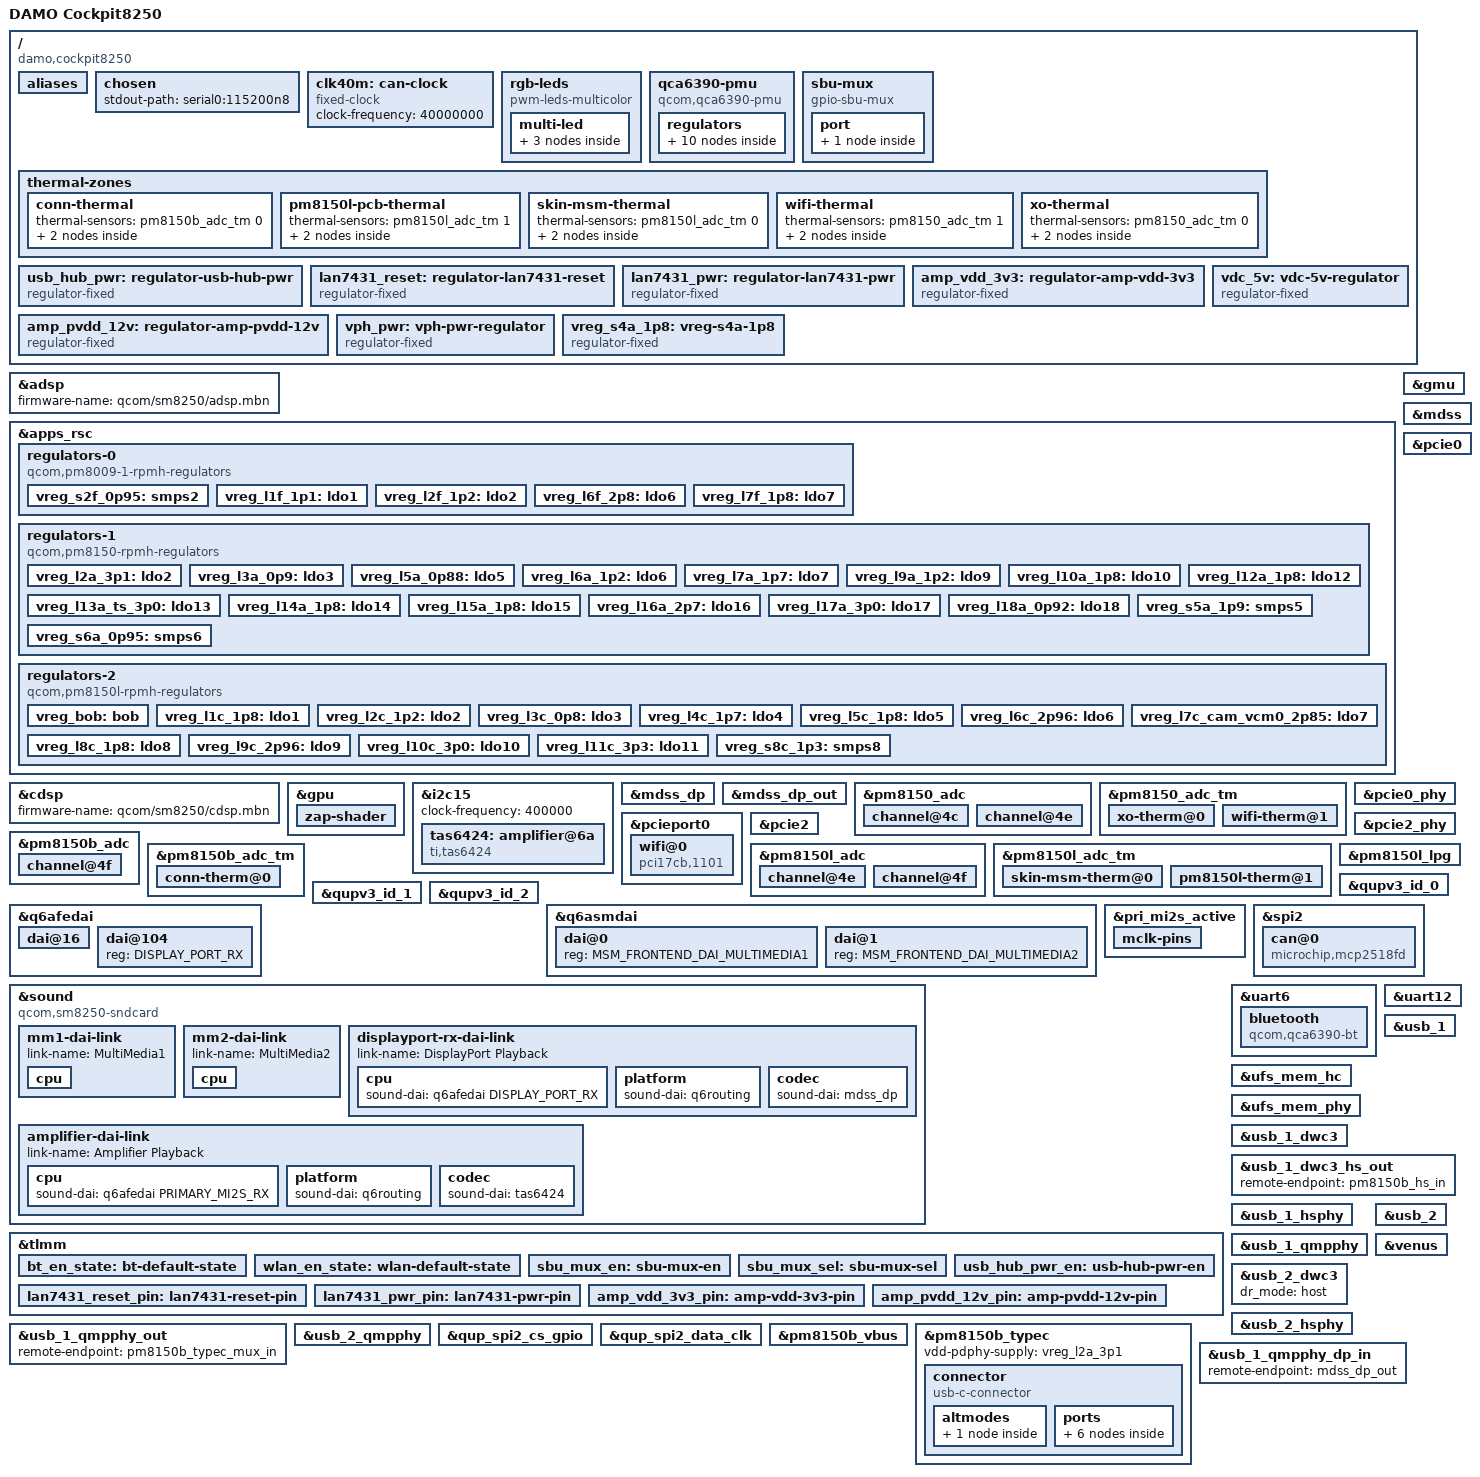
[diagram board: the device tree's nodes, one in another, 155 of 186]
// SPDX-License-Identifier: BSD-3-Clause
/*
 * Copyright (c) 2020, Linaro Ltd.
 * Copyright (c) 2025 retro98boy <retro98boy@qq.com>
 */

/dts-v1/;

#include <dt-bindings/leds/common.h>
#include <dt-bindings/regulator/qcom,rpmh-regulator.h>
#include <dt-bindings/sound/qcom,q6afe.h>
#include <dt-bindings/sound/qcom,q6asm.h>
#include <dt-bindings/usb/pd.h>
#include "sm8250.dtsi"
#include "pm8150.dtsi"
#include "pm8150b.dtsi"
#include "pm8150l.dtsi"

/ {
	model = "DAMO Cockpit8250";
	compatible = "damo,cockpit8250", "qcom,sm8250";
	/* required for abl to select correct board */
	qcom,msm-id = <0x1e1 0x20001>;
	qcom,board-id = <0x1001f 0x01>;

	aliases {
		serial0 = &uart12;
		serial1 = &uart6;
	};

	chosen {
		stdout-path = "serial0:115200n8";
	};

	clk40m: can-clock {
		compatible = "fixed-clock";
		#clock-cells = <0>;
		clock-frequency = <40000000>;
	};

	rgb-leds {
		compatible = "pwm-leds-multicolor";

		multi-led {
			color = <LED_COLOR_ID_RGB>;
			max-brightness = <255>;

			led-red {
				color = <LED_COLOR_ID_RED>;
				pwms = <&pm8150l_lpg 0 1000000 0>;
			};

			led-green {
				color = <LED_COLOR_ID_GREEN>;
				pwms = <&pm8150l_lpg 1 1000000 0>;
			};

			led-blue {
				color = <LED_COLOR_ID_BLUE>;
				pwms = <&pm8150l_lpg 2 1000000 0>;
			};
		};
	};

	qca6390-pmu {
		compatible = "qcom,qca6390-pmu";

		pinctrl-names = "default";
		pinctrl-0 = <&bt_en_state>, <&wlan_en_state>;

		vddaon-supply = <&vreg_s6a_0p95>;
		vddpmu-supply = <&vreg_s2f_0p95>;
		vddrfa0p95-supply = <&vreg_s2f_0p95>;
		vddrfa1p3-supply = <&vreg_s8c_1p3>;
		vddrfa1p9-supply = <&vreg_s5a_1p9>;
		vddpcie1p3-supply = <&vreg_s8c_1p3>;
		vddpcie1p9-supply = <&vreg_s5a_1p9>;
		vddio-supply = <&vreg_s4a_1p8>;

		wlan-enable-gpios = <&tlmm 20 GPIO_ACTIVE_HIGH>;
		bt-enable-gpios = <&tlmm 21 GPIO_ACTIVE_HIGH>;

		regulators {
			vreg_pmu_rfa_cmn: ldo0 {
				regulator-name = "vreg_pmu_rfa_cmn";
			};

			vreg_pmu_aon_0p59: ldo1 {
				regulator-name = "vreg_pmu_aon_0p59";
			};

			vreg_pmu_wlcx_0p8: ldo2 {
				regulator-name = "vreg_pmu_wlcx_0p8";
			};

			vreg_pmu_wlmx_0p85: ldo3 {
				regulator-name = "vreg_pmu_wlmx_0p85";
			};

			vreg_pmu_btcmx_0p85: ldo4 {
				regulator-name = "vreg_pmu_btcmx_0p85";
			};

			vreg_pmu_rfa_0p8: ldo5 {
				regulator-name = "vreg_pmu_rfa_0p8";
			};

			vreg_pmu_rfa_1p2: ldo6 {
				regulator-name = "vreg_pmu_rfa_1p2";
			};

			vreg_pmu_rfa_1p7: ldo7 {
				regulator-name = "vreg_pmu_rfa_1p7";
			};

			vreg_pmu_pcie_0p9: ldo8 {
				regulator-name = "vreg_pmu_pcie_0p9";
			};

			vreg_pmu_pcie_1p8: ldo9 {
				regulator-name = "vreg_pmu_pcie_1p8";
			};
		};
	};

	sbu-mux {
		compatible = "gpio-sbu-mux";
		pinctrl-names = "default";
		pinctrl-0 = <&sbu_mux_en &sbu_mux_sel>;
		enable-gpios = <&tlmm 9 GPIO_ACTIVE_LOW>;
		select-gpios = <&tlmm 8 GPIO_ACTIVE_HIGH>;

		mode-switch;
		orientation-switch;

		port {
			sbu_mux_in: endpoint {
				remote-endpoint = <&pm8150b_typec_sbu_out>;
			};
		};
	};

	thermal-zones {
		conn-thermal {
			thermal-sensors = <&pm8150b_adc_tm 0>;

			trips {
				active-config0 {
					temperature = <125000>;
					hysteresis = <1000>;
					type = "critical";
				};
			};
		};

		pm8150l-pcb-thermal {
			thermal-sensors = <&pm8150l_adc_tm 1>;

			trips {
				active-config0 {
					temperature = <50000>;
					hysteresis = <4000>;
					type = "passive";
				};
			};
		};

		skin-msm-thermal {
			thermal-sensors = <&pm8150l_adc_tm 0>;

			trips {
				active-config0 {
					temperature = <50000>;
					hysteresis = <4000>;
					type = "passive";
				};
			};
		};

		wifi-thermal {
			thermal-sensors = <&pm8150_adc_tm 1>;

			trips {
				active-config0 {
					temperature = <52000>;
					hysteresis = <4000>;
					type = "passive";
				};
			};
		};

		xo-thermal {
			thermal-sensors = <&pm8150_adc_tm 0>;

			trips {
				active-config0 {
					temperature = <50000>;
					hysteresis = <4000>;
					type = "passive";
				};
			};
		};
	};

	usb_hub_pwr: regulator-usb-hub-pwr {
		compatible = "regulator-fixed";
		enable-active-high;
		gpio = <&tlmm 2 GPIO_ACTIVE_HIGH>;
		pinctrl-names = "default";
		pinctrl-0 = <&usb_hub_pwr_en>;
		regulator-name = "usb_hub_pwr";
		regulator-always-on;
		regulator-boot-on;
	};

	lan7431_reset: regulator-lan7431-reset {
		compatible = "regulator-fixed";
		enable-active-high;
		gpio = <&tlmm 10 GPIO_ACTIVE_HIGH>;
		pinctrl-names = "default";
		pinctrl-0 = <&lan7431_reset_pin>;
		regulator-name = "lan7431_reset";
		regulator-always-on;
		regulator-boot-on;
	};

	lan7431_pwr: regulator-lan7431-pwr {
		compatible = "regulator-fixed";
		enable-active-high;
		gpio = <&tlmm 53 GPIO_ACTIVE_HIGH>;
		pinctrl-names = "default";
		pinctrl-0 = <&lan7431_pwr_pin>;
		regulator-name = "lan7431_pwr";
		regulator-always-on;
		regulator-boot-on;
	};

	amp_vdd_3v3: regulator-amp-vdd-3v3 {
		compatible = "regulator-fixed";
		enable-active-high;
		gpio = <&tlmm 12 GPIO_ACTIVE_HIGH>;
		pinctrl-names = "default";
		pinctrl-0 = <&amp_vdd_3v3_pin>;
		regulator-name = "amp_vdd_3v3";
		regulator-always-on;
		regulator-boot-on;
	};

	amp_pvdd_12v: regulator-amp-pvdd-12v {
		compatible = "regulator-fixed";
		enable-active-high;
		gpio = <&tlmm 13 GPIO_ACTIVE_HIGH>;
		pinctrl-names = "default";
		pinctrl-0 = <&amp_pvdd_12v_pin>;
		regulator-name = "amp_pvdd_12v";
		regulator-always-on;
		regulator-boot-on;
	};

	vdc_5v: vdc-5v-regulator {
		compatible = "regulator-fixed";
		regulator-name = "VDC_5V";

		regulator-min-microvolt = <5000000>;
		regulator-max-microvolt = <5000000>;
		regulator-always-on;
		vin-supply = <&vreg_l11c_3p3>;
	};

	vph_pwr: vph-pwr-regulator {
		compatible = "regulator-fixed";
		regulator-name = "vph_pwr";
		regulator-min-microvolt = <3700000>;
		regulator-max-microvolt = <3700000>;
		regulator-always-on;
	};

	vreg_s4a_1p8: vreg-s4a-1p8 {
		compatible = "regulator-fixed";
		regulator-name = "vreg_s4a_1p8";
		regulator-min-microvolt = <1800000>;
		regulator-max-microvolt = <1800000>;
		regulator-always-on;
	};
};

&adsp {
	status = "okay";
	firmware-name = "qcom/sm8250/adsp.mbn";
};

&apps_rsc {
	regulators-0 {
		compatible = "qcom,pm8009-1-rpmh-regulators";
		qcom,pmic-id = "f";

		vdd-s1-supply = <&vph_pwr>;
		vdd-s2-supply = <&vph_pwr>;
		vdd-l2-supply = <&vreg_s8c_1p3>;
		vdd-l5-l6-supply = <&vreg_bob>;
		vdd-l7-supply = <&vreg_s4a_1p8>;

		vreg_s2f_0p95: smps2 {
			regulator-name = "vreg_s2f_0p95";
			regulator-min-microvolt = <900000>;
			regulator-max-microvolt = <952000>;
			regulator-initial-mode = <RPMH_REGULATOR_MODE_AUTO>;
		};

		vreg_l1f_1p1: ldo1 {
			regulator-name = "vreg_l1f_1p1";
			regulator-min-microvolt = <1104000>;
			regulator-max-microvolt = <1104000>;
			regulator-initial-mode = <RPMH_REGULATOR_MODE_HPM>;
		};

		vreg_l2f_1p2: ldo2 {
			regulator-name = "vreg_l2f_1p2";
			regulator-min-microvolt = <1200000>;
			regulator-max-microvolt = <1200000>;
			regulator-initial-mode = <RPMH_REGULATOR_MODE_HPM>;
		};

		vreg_l6f_2p8: ldo6 {
			regulator-name = "vreg_l6f_2p8";
			regulator-min-microvolt = <2800000>;
			regulator-max-microvolt = <2800000>;
			regulator-initial-mode = <RPMH_REGULATOR_MODE_HPM>;
		};

		vreg_l7f_1p8: ldo7 {
			regulator-name = "vreg_l7f_1p8";
			regulator-min-microvolt = <1800000>;
			regulator-max-microvolt = <1800000>;
			regulator-initial-mode = <RPMH_REGULATOR_MODE_HPM>;
		};
	};

	regulators-1 {
		compatible = "qcom,pm8150-rpmh-regulators";
		qcom,pmic-id = "a";

		vdd-s1-supply = <&vph_pwr>;
		vdd-s2-supply = <&vph_pwr>;
		vdd-s3-supply = <&vph_pwr>;
		vdd-s4-supply = <&vph_pwr>;
		vdd-s5-supply = <&vph_pwr>;
		vdd-s6-supply = <&vph_pwr>;
		vdd-s7-supply = <&vph_pwr>;
		vdd-s8-supply = <&vph_pwr>;
		vdd-s9-supply = <&vph_pwr>;
		vdd-s10-supply = <&vph_pwr>;
		vdd-l2-l10-supply = <&vreg_bob>;
		vdd-l3-l4-l5-l18-supply = <&vreg_s6a_0p95>;
		vdd-l6-l9-supply = <&vreg_s8c_1p3>;
		vdd-l7-l12-l14-l15-supply = <&vreg_s5a_1p9>;
		vdd-l13-l16-l17-supply = <&vreg_bob>;

		vreg_l2a_3p1: ldo2 {
			regulator-name = "vreg_l2a_3p1";
			regulator-min-microvolt = <3072000>;
			regulator-max-microvolt = <3072000>;
			regulator-initial-mode = <RPMH_REGULATOR_MODE_HPM>;
		};

		vreg_l3a_0p9: ldo3 {
			regulator-name = "vreg_l3a_0p9";
			regulator-min-microvolt = <928000>;
			regulator-max-microvolt = <932000>;
			regulator-initial-mode = <RPMH_REGULATOR_MODE_HPM>;
		};

		vreg_l5a_0p88: ldo5 {
			regulator-name = "vreg_l5a_0p88";
			regulator-min-microvolt = <880000>;
			regulator-max-microvolt = <880000>;
			regulator-initial-mode = <RPMH_REGULATOR_MODE_HPM>;
		};

		vreg_l6a_1p2: ldo6 {
			regulator-name = "vreg_l6a_1p2";
			regulator-min-microvolt = <1200000>;
			regulator-max-microvolt = <1200000>;
			regulator-initial-mode = <RPMH_REGULATOR_MODE_HPM>;
		};

		vreg_l7a_1p7: ldo7 {
			regulator-name = "vreg_l7a_1p7";
			regulator-min-microvolt = <1704000>;
			regulator-max-microvolt = <1800000>;
			regulator-initial-mode = <RPMH_REGULATOR_MODE_HPM>;
		};

		vreg_l9a_1p2: ldo9 {
			regulator-name = "vreg_l9a_1p2";
			regulator-min-microvolt = <1200000>;
			regulator-max-microvolt = <1200000>;
			regulator-initial-mode = <RPMH_REGULATOR_MODE_HPM>;
		};

		vreg_l10a_1p8: ldo10 {
			regulator-name = "vreg_l10a_1p8";
			regulator-min-microvolt = <1800000>;
			regulator-max-microvolt = <1800000>;
			regulator-initial-mode = <RPMH_REGULATOR_MODE_HPM>;
		};

		vreg_l12a_1p8: ldo12 {
			regulator-name = "vreg_l12a_1p8";
			regulator-min-microvolt = <1800000>;
			regulator-max-microvolt = <1800000>;
			regulator-initial-mode = <RPMH_REGULATOR_MODE_HPM>;
		};

		vreg_l13a_ts_3p0: ldo13 {
			regulator-name = "vreg_l13a_ts_3p0";
			regulator-min-microvolt = <3008000>;
			regulator-max-microvolt = <3008000>;
			regulator-initial-mode = <RPMH_REGULATOR_MODE_HPM>;
		};

		vreg_l14a_1p8: ldo14 {
			regulator-name = "vreg_l14a_1p8";
			regulator-min-microvolt = <1800000>;
			regulator-max-microvolt = <1880000>;
			regulator-initial-mode = <RPMH_REGULATOR_MODE_HPM>;
		};

		vreg_l15a_1p8: ldo15 {
			regulator-name = "vreg_l15a_1p8";
			regulator-min-microvolt = <1800000>;
			regulator-max-microvolt = <1800000>;
			regulator-initial-mode = <RPMH_REGULATOR_MODE_HPM>;
		};

		vreg_l16a_2p7: ldo16 {
			regulator-name = "vreg_l16a_2p7";
			regulator-min-microvolt = <2704000>;
			regulator-max-microvolt = <2960000>;
			regulator-initial-mode = <RPMH_REGULATOR_MODE_HPM>;
		};

		vreg_l17a_3p0: ldo17 {
			regulator-name = "vreg_l17a_3p0";
			regulator-min-microvolt = <2856000>;
			regulator-max-microvolt = <3008000>;
			regulator-initial-mode = <RPMH_REGULATOR_MODE_HPM>;
		};

		vreg_l18a_0p92: ldo18 {
			regulator-name = "vreg_l18a_0p92";
			regulator-min-microvolt = <800000>;
			regulator-max-microvolt = <912000>;
			regulator-initial-mode = <RPMH_REGULATOR_MODE_HPM>;
		};

		vreg_s5a_1p9: smps5 {
			regulator-name = "vreg_s5a_1p9";
			regulator-min-microvolt = <1904000>;
			regulator-max-microvolt = <2000000>;
			regulator-initial-mode = <RPMH_REGULATOR_MODE_HPM>;
		};

		vreg_s6a_0p95: smps6 {
			regulator-name = "vreg_s6a_0p95";
			regulator-min-microvolt = <920000>;
			regulator-max-microvolt = <1128000>;
			regulator-initial-mode = <RPMH_REGULATOR_MODE_HPM>;
		};
	};

	regulators-2 {
		compatible = "qcom,pm8150l-rpmh-regulators";
		qcom,pmic-id = "c";

		vdd-s1-supply = <&vph_pwr>;
		vdd-s2-supply = <&vph_pwr>;
		vdd-s3-supply = <&vph_pwr>;
		vdd-s4-supply = <&vph_pwr>;
		vdd-s5-supply = <&vph_pwr>;
		vdd-s6-supply = <&vph_pwr>;
		vdd-s7-supply = <&vph_pwr>;
		vdd-s8-supply = <&vph_pwr>;
		vdd-l1-l8-supply = <&vreg_s4a_1p8>;
		vdd-l2-l3-supply = <&vreg_s8c_1p3>;
		vdd-l4-l5-l6-supply = <&vreg_bob>;
		vdd-l7-l11-supply = <&vreg_bob>;
		vdd-l9-l10-supply = <&vreg_bob>;
		vdd-bob-supply = <&vph_pwr>;

		vreg_bob: bob {
			regulator-name = "vreg_bob";
			regulator-min-microvolt = <3008000>;
			regulator-max-microvolt = <4000000>;
			regulator-initial-mode = <RPMH_REGULATOR_MODE_AUTO>;
		};

		vreg_l1c_1p8: ldo1 {
			regulator-name = "vreg_l1c_1p8";
			regulator-min-microvolt = <1800000>;
			regulator-max-microvolt = <1800000>;
			regulator-initial-mode = <RPMH_REGULATOR_MODE_HPM>;
		};

		vreg_l2c_1p2: ldo2 {
			regulator-name = "vreg_l2c_1p2";
			regulator-min-microvolt = <1200000>;
			regulator-max-microvolt = <1200000>;
			regulator-initial-mode = <RPMH_REGULATOR_MODE_HPM>;
		};

		vreg_l3c_0p8: ldo3 {
			regulator-name = "vreg_l3c_0p8";
			regulator-min-microvolt = <800000>;
			regulator-max-microvolt = <800000>;
			regulator-initial-mode = <RPMH_REGULATOR_MODE_HPM>;
		};

		vreg_l4c_1p7: ldo4 {
			regulator-name = "vreg_l4c_1p7";
			regulator-min-microvolt = <1704000>;
			regulator-max-microvolt = <2928000>;
			regulator-initial-mode = <RPMH_REGULATOR_MODE_HPM>;
		};

		vreg_l5c_1p8: ldo5 {
			regulator-name = "vreg_l5c_1p8";
			regulator-min-microvolt = <1800000>;
			regulator-max-microvolt = <2928000>;
			regulator-initial-mode = <RPMH_REGULATOR_MODE_HPM>;
		};

		vreg_l6c_2p96: ldo6 {
			regulator-name = "vreg_l6c_2p96";
			regulator-min-microvolt = <1800000>;
			regulator-max-microvolt = <2960000>;
			regulator-initial-mode = <RPMH_REGULATOR_MODE_HPM>;
		};

		vreg_l7c_cam_vcm0_2p85: ldo7 {
			regulator-name = "vreg_l7c_cam_vcm0_2p85";
			regulator-min-microvolt = <2856000>;
			regulator-max-microvolt = <3104000>;
			regulator-initial-mode = <RPMH_REGULATOR_MODE_HPM>;
		};

		vreg_l8c_1p8: ldo8 {
			regulator-name = "vreg_l8c_1p8";
			regulator-min-microvolt = <1800000>;
			regulator-max-microvolt = <1800000>;
			regulator-initial-mode = <RPMH_REGULATOR_MODE_HPM>;
		};

		vreg_l9c_2p96: ldo9 {
			regulator-name = "vreg_l9c_2p96";
			regulator-min-microvolt = <2704000>;
			regulator-max-microvolt = <2960000>;
			regulator-initial-mode = <RPMH_REGULATOR_MODE_HPM>;
		};

		vreg_l10c_3p0: ldo10 {
			regulator-name = "vreg_l10c_3p0";
			regulator-min-microvolt = <3000000>;
			regulator-max-microvolt = <3000000>;
			regulator-initial-mode = <RPMH_REGULATOR_MODE_HPM>;
		};

		vreg_l11c_3p3: ldo11 {
			regulator-name = "vreg_l11c_3p3";
			regulator-min-microvolt = <3296000>;
			regulator-max-microvolt = <3296000>;
			regulator-initial-mode = <RPMH_REGULATOR_MODE_HPM>;
			regulator-always-on;
		};

		vreg_s8c_1p3: smps8 {
			regulator-name = "vreg_s8c_1p3";
			regulator-min-microvolt = <1352000>;
			regulator-max-microvolt = <1352000>;
			regulator-initial-mode = <RPMH_REGULATOR_MODE_HPM>;
		};
	};
};

&cdsp {
	status = "okay";
	firmware-name = "qcom/sm8250/cdsp.mbn";
};

&gmu {
	status = "okay";
};

&gpu {
	status = "okay";

	zap-shader {
		memory-region = <&gpu_mem>;
		firmware-name = "qcom/sm8250/a650_zap.mbn";
	};
};

&i2c15 {
	status = "okay";
	clock-frequency = <400000>;

	tas6424: amplifier@6a {
		sound-name-prefix = "Amplifier";
		compatible = "ti,tas6424";
		reg = <0x6a>;
		#sound-dai-cells = <0>;

		/* dvdd-supply = <&amp_vdd_3v3>; */
		/* pvdd-supply = <&amp_pvdd_12v>; */
		standby-gpios = <&tlmm 41 GPIO_ACTIVE_LOW>;
		mute-gpios = <&tlmm 42 GPIO_ACTIVE_LOW>;
	};
};

&mdss {
	status = "okay";
};

&mdss_dp {
	status = "okay";
};

&mdss_dp_out {
	data-lanes = <2 3>;
	remote-endpoint = <&usb_1_qmpphy_dp_in>;
};

&pm8150_adc {
	channel@4c {
		reg = <ADC5_XO_THERM_100K_PU>;
		qcom,ratiometric;
		qcom,hw-settle-time = <200>;
		label = "xo_therm";
	};

	channel@4e {
		reg = <ADC5_AMUX_THM2_100K_PU>;
		qcom,ratiometric;
		qcom,hw-settle-time = <200>;
		label = "wifi_therm";
	};
};

&pm8150_adc_tm {
	status = "okay";

	xo-therm@0 {
		reg = <0>;
		io-channels = <&pm8150_adc ADC5_XO_THERM_100K_PU>;
		qcom,ratiometric;
		qcom,hw-settle-time-us = <200>;
	};

	wifi-therm@1 {
		reg = <1>;
		io-channels = <&pm8150_adc ADC5_AMUX_THM2_100K_PU>;
		qcom,ratiometric;
		qcom,hw-settle-time-us = <200>;
	};
};

&pcie0 {
	status = "okay";
};

&pcie0_phy {
	status = "okay";
	vdda-phy-supply = <&vreg_l5a_0p88>;
	vdda-pll-supply = <&vreg_l9a_1p2>;
};

&pcieport0 {
	wifi@0 {
		compatible = "pci17cb,1101";
		reg = <0x10000 0x0 0x0 0x0 0x0>;

		vddrfacmn-supply = <&vreg_pmu_rfa_cmn>;
		vddaon-supply = <&vreg_pmu_aon_0p59>;
		vddwlcx-supply = <&vreg_pmu_wlcx_0p8>;
		vddwlmx-supply = <&vreg_pmu_wlmx_0p85>;
		vddrfa0p8-supply = <&vreg_pmu_rfa_0p8>;
		vddrfa1p2-supply = <&vreg_pmu_rfa_1p2>;
		vddrfa1p7-supply = <&vreg_pmu_rfa_1p7>;
		vddpcie0p9-supply = <&vreg_pmu_pcie_0p9>;
		vddpcie1p8-supply = <&vreg_pmu_pcie_1p8>;
	};
};

/*
 * LAN7431
 * PERST# <-> tlmm 85
 * WAKE# <-> tlmm 87
 * RESET_N <-> tlmm 10
 * AVDD12 VDD_OTP VDD12CORE VDD12_SW_FB VDD_SW_IN VDD12_SW_OUT VDD_REG_IN VDD25_REG_OUT VPH VPTX VP <-> tlmm 53
 */
&pcie2 {
	status = "okay";
};

&pcie2_phy {
	status = "okay";
	vdda-phy-supply = <&vreg_l5a_0p88>;
	vdda-pll-supply = <&vreg_l9a_1p2>;
};

&pm8150b_adc {
	channel@4f {
		reg = <ADC5_AMUX_THM3_100K_PU>;
		qcom,ratiometric;
		qcom,hw-settle-time = <200>;
		label = "conn_therm";
	};
};

&pm8150b_adc_tm {
	status = "okay";

	conn-therm@0 {
		reg = <0>;
		io-channels = <&pm8150b_adc ADC5_AMUX_THM3_100K_PU>;
		qcom,ratiometric;
		qcom,hw-settle-time-us = <200>;
	};
};

&pm8150l_adc {
	channel@4e {
		reg = <ADC5_AMUX_THM2_100K_PU>;
		qcom,ratiometric;
		qcom,hw-settle-time = <200>;
		label = "skin_msm_therm";
	};

	channel@4f {
		reg = <ADC5_AMUX_THM3_100K_PU>;
		qcom,ratiometric;
		qcom,hw-settle-time = <200>;
		label = "pm8150l_therm";
	};
};

&pm8150l_adc_tm {
	status = "okay";

	skin-msm-therm@0 {
		reg = <0>;
		io-channels = <&pm8150l_adc ADC5_AMUX_THM2_100K_PU>;
		qcom,ratiometric;
		qcom,hw-settle-time-us = <200>;
	};

	pm8150l-therm@1 {
		reg = <1>;
		io-channels = <&pm8150l_adc ADC5_AMUX_THM3_100K_PU>;
		qcom,ratiometric;
		qcom,hw-settle-time-us = <200>;
	};
};

&pm8150l_lpg {
	status = "okay";
};

&qupv3_id_0 {
	status = "okay";
	firmware-name = "qcom/sm8250/damo-cockpit8250/qupfw.mbn";
};

&qupv3_id_1 {
	status = "okay";
	firmware-name = "qcom/sm8250/damo-cockpit8250/qupfw.mbn";
};

&qupv3_id_2 {
	status = "okay";
	firmware-name = "qcom/sm8250/damo-cockpit8250/qupfw.mbn";
};

&q6afedai {
	/* PRIM I2S Uses 2 I2S SD Line for audio on TAS6424 amplifier */
	dai@16 {
		reg = <PRIMARY_MI2S_RX>;
		qcom,sd-lines = <0 1>;
	};

	dai@104 {
		reg = <DISPLAY_PORT_RX>;
	};
};

&q6asmdai {
	dai@0 {
		reg = <MSM_FRONTEND_DAI_MULTIMEDIA1>;
	};

	dai@1 {
		reg = <MSM_FRONTEND_DAI_MULTIMEDIA2>;
	};
};

/*
 * TAS6424 MCLK <-> tlmm 136
 * TAS6424 SCLK <-> tlmm 138
 * TAS6424 FSYNC <-> tlmm 141
 * TAS6424 SDIN1 <-> tlmm 139
 * TAS6424 SDIN2 <-> tlmm 140
 */
&pri_mi2s_active {
	mclk-pins {
		pins = "gpio136";
		function = "pri_mi2s";
		drive-strength = <8>;
		bias-disable;
	};
};

&sound {
	compatible = "qcom,sm8250-sndcard";
	pinctrl-0 = <&pri_mi2s_active>;
	pinctrl-names = "default";
	model = "damo-cockpit8250";
	audio-routing =
		"Amplifier DAC IN", "MultiMedia2 Playback";

	mm1-dai-link {
		link-name = "MultiMedia1";

		cpu {
			sound-dai = <&q6asmdai MSM_FRONTEND_DAI_MULTIMEDIA1>;
		};
	};

	mm2-dai-link {
		link-name = "MultiMedia2";

		cpu {
			sound-dai = <&q6asmdai MSM_FRONTEND_DAI_MULTIMEDIA2>;
		};
	};

	displayport-rx-dai-link {
		link-name = "DisplayPort Playback";

		cpu {
			sound-dai = <&q6afedai DISPLAY_PORT_RX>;
		};

		platform {
			sound-dai = <&q6routing>;
		};

		codec {
			sound-dai = <&mdss_dp>;
		};
	};

	amplifier-dai-link {
		link-name = "Amplifier Playback";

		cpu {
			sound-dai = <&q6afedai PRIMARY_MI2S_RX>;
		};

		platform {
			sound-dai = <&q6routing>;
		};

		codec {
			sound-dai = <&tas6424>;
		};
	};
};

&spi2 {
	status = "okay";
	pinctrl-names = "default";
	pinctrl-0 = <&qup_spi2_data_clk>, <&qup_spi2_cs_gpio>;
	cs-gpios = <&tlmm 118 GPIO_ACTIVE_LOW>;

	can@0 {
		compatible = "microchip,mcp2518fd";
		reg = <0>;
		clocks = <&clk40m>;
		interrupts-extended = <&tlmm 11 IRQ_TYPE_LEVEL_LOW>;
		spi-max-frequency = <10000000>;
		vdd-supply = <&vdc_5v>;
		xceiver-supply = <&vdc_5v>;
	};
};

&tlmm {
	bt_en_state: bt-default-state {
		pins = "gpio21";
		function = "gpio";
		drive-strength = <16>;
		output-low;
		bias-pull-up;
	};

	wlan_en_state: wlan-default-state {
		pins = "gpio20";
		function = "gpio";
		drive-strength = <16>;
		output-low;
		bias-pull-up;
	};

	sbu_mux_en: sbu-mux-en {
		pins = "gpio9";
		function = "gpio";
		output-high;
		bias-pull-up;
	};

	sbu_mux_sel: sbu-mux-sel {
		pins = "gpio8";
		function = "gpio";
		output-low;
		bias-pull-default;
	};

	usb_hub_pwr_en: usb-hub-pwr-en {
		pins = "gpio2";
		function = "gpio";
		output-low;
		bias-pull-up;
	};

	lan7431_reset_pin: lan7431-reset-pin {
		pins = "gpio10";
		function = "gpio";
		output-low;
		bias-pull-up;
	};

	lan7431_pwr_pin: lan7431-pwr-pin {
		pins = "gpio53";
		function = "gpio";
		output-low;
		bias-pull-up;
	};

	amp_vdd_3v3_pin: amp-vdd-3v3-pin {
		pins = "gpio12";
		function = "gpio";
		output-high;
		bias-pull-up;
	};

	amp_pvdd_12v_pin: amp-pvdd-12v-pin {
		pins = "gpio13";
		function = "gpio";
		output-high;
		bias-pull-up;
	};
};

&uart6 {
	status = "okay";

	bluetooth {
		compatible = "qcom,qca6390-bt";

		vddrfacmn-supply = <&vreg_pmu_rfa_cmn>;
		vddaon-supply = <&vreg_pmu_aon_0p59>;
		vddbtcmx-supply = <&vreg_pmu_btcmx_0p85>;
		vddrfa0p8-supply = <&vreg_pmu_rfa_0p8>;
		vddrfa1p2-supply = <&vreg_pmu_rfa_1p2>;
		vddrfa1p7-supply = <&vreg_pmu_rfa_1p7>;
	};
};

&uart12 {
	status = "okay";
};

#if 0
/*
 * NSiP83086 RS485
 * R <-> tlmm 51
 * /RE DE high <-> tlmm 50 low
 */
&uart16 {
	status = "okay";
};
#endif

&ufs_mem_hc {
	status = "okay";

	vcc-supply = <&vreg_l17a_3p0>;
	vcc-max-microamp = <800000>;
	vccq-supply = <&vreg_l6a_1p2>;
	vccq-max-microamp = <800000>;
	vccq2-supply = <&vreg_s4a_1p8>;
	vccq2-max-microamp = <800000>;
};

&ufs_mem_phy {
	status = "okay";

	vdda-phy-supply = <&vreg_l5a_0p88>;
	vdda-pll-supply = <&vreg_l9a_1p2>;
};

&usb_1 {
	status = "okay";
};

&usb_1_dwc3 {
	dr_mode = "otg";
	usb-role-switch;
};

&usb_1_dwc3_hs_out {
	remote-endpoint = <&pm8150b_hs_in>;
};

&usb_1_hsphy {
	status = "okay";

	vdda-pll-supply = <&vreg_l5a_0p88>;
	vdda33-supply = <&vreg_l2a_3p1>;
	vdda18-supply = <&vreg_l12a_1p8>;
};

&usb_1_qmpphy {
	status = "okay";

	vdda-phy-supply = <&vreg_l9a_1p2>;
	vdda-pll-supply = <&vreg_l18a_0p92>;
};

&usb_1_qmpphy_out {
	remote-endpoint = <&pm8150b_typec_mux_in>;
};

&usb_2 {
	status = "okay";
};

&usb_2_dwc3 {
	dr_mode = "host";
};

&usb_2_hsphy {
	status = "okay";

	vdda-pll-supply = <&vreg_l5a_0p88>;
	vdda33-supply = <&vreg_l2a_3p1>;
	vdda18-supply = <&vreg_l12a_1p8>;
};

&usb_2_qmpphy {
	status = "okay";

	vdda-phy-supply = <&vreg_l9a_1p2>;
	vdda-pll-supply = <&vreg_l18a_0p92>;
};

&venus {
	status = "okay";
};

/* PINCTRL - additions to nodes defined in sm8250.dtsi */
&qup_spi2_cs_gpio {
	drive-strength = <6>;
	bias-disable;
};

&qup_spi2_data_clk {
	drive-strength = <6>;
	bias-disable;
};

&pm8150b_vbus {
	regulator-min-microamp = <500000>;
	regulator-max-microamp = <3000000>;
	status = "okay";
};

&pm8150b_typec {
	status = "okay";

	vdd-pdphy-supply = <&vreg_l2a_3p1>;

	connector {
		compatible = "usb-c-connector";

		/* power-role = "dual"; */
		power-role = "source";
		data-role = "dual";
		self-powered;

		source-pdos = <PDO_FIXED(5000, 3000,
					 PDO_FIXED_DUAL_ROLE |
					 PDO_FIXED_USB_COMM |
					 PDO_FIXED_DATA_SWAP)>;

		altmodes {
			displayport {
				svid = /bits/ 16 <0xff01>;
				vdo = <0x00001c46>;
			};
		};

		ports {
			#address-cells = <1>;
			#size-cells = <0>;

			port@0 {
				reg = <0>;

				pm8150b_hs_in: endpoint {
					remote-endpoint = <&usb_1_dwc3_hs_out>;
				};
			};

			port@1 {
				reg = <1>;

				pm8150b_typec_mux_in: endpoint {
					remote-endpoint = <&usb_1_qmpphy_out>;
				};
			};

			port@2 {
				reg = <2>;

				pm8150b_typec_sbu_out: endpoint {
					remote-endpoint = <&sbu_mux_in>;
				};
			};
		};
	};
};

&usb_1_qmpphy_dp_in {
	remote-endpoint = <&mdss_dp_out>;
};
